VERSION ""

NS_ :

BS_:

BU_:

BO_ 2371550974 Chopper_Command: 8 Vector__XXX
 SG_ Faults_Clear : 2|2@1+ (1,0) [0|3] "" Vector__XXX
 SG_ Enable_Command : 0|2@1+ (1,0) [0|3] "" Vector__XXX

BO_ 2381595134 Chopper_State2: 8 Vector__XXX
 SG_ Chopper_Duty : 16|16@1+ (0.1,0) [0|100] "%" Vector__XXX
 SG_ Chopper_FSM_State : 0|16@1+ (1,0) [0|65535] "" Vector__XXX

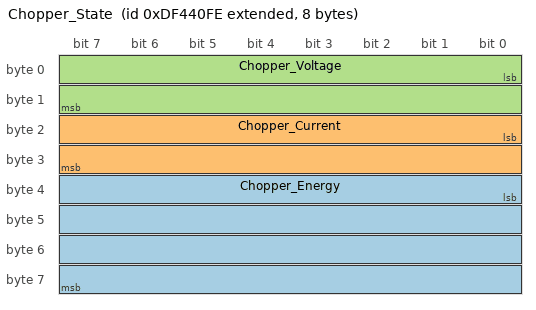
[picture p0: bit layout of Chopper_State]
BO_ 2381594878 Chopper_State: 8 Vector__XXX
 SG_ Chopper_Energy : 32|32@1+ (1,0) [0|4294967295] "J" Vector__XXX
 SG_ Chopper_Current : 16|16@1+ (0.1,0) [0|100] "Amps" Vector__XXX
 SG_ Chopper_Voltage : 0|16@1+ (0.1,0) [0|1000] "V" Vector__XXX

CM_ BO_ 2371550974 "Chopper command message";
CM_ SG_ 2371550974 Faults_Clear "Faults clear command";
CM_ SG_ 2371550974 Enable_Command "Turn on/off command";
CM_ BO_ 2381595134 "Second chopper state message";
CM_ SG_ 2381595134 Chopper_Duty "Current chopper's duty cycle";
CM_ SG_ 2381595134 Chopper_FSM_State "Current chopper's FSM state (0x0 - Initialization, 0x1 - Idle, 0x2 - Run, 0x8000 - Fault)";
CM_ BO_ 2381594878 "First chopper state message";
CM_ SG_ 2381594878 Chopper_Energy "Calculated energy dissipated on chopper resistor";
CM_ SG_ 2381594878 Chopper_Current "Calculated current through chopper resistor";
CM_ SG_ 2381594878 Chopper_Voltage "Calculated voltage on chopper resistor";
BA_DEF_ SG_  "SigType" ENUM  "Default","Range","RangeSigned","ASCII","Discrete","Control","ReferencePGN","DTC","StringDelimiter","StringLength","StringLengthControl","MessageCounter","MessageChecksum";
BA_DEF_ SG_  "GenSigEVName" STRING ;
BA_DEF_ SG_  "GenSigILSupport" ENUM  "No","Yes";
BA_DEF_ SG_  "GenSigSendType" ENUM  "Cyclic","OnWrite","OnWriteWithRepetition","OnChange","OnChangeWithRepetition","IfActive","IfActiveWithRepetition","NoSigSendType";
BA_DEF_ BO_  "GenMsgILSupport" ENUM  "No","Yes";
BA_DEF_ BU_  "NmStationAddress" INT 0 255;
BA_DEF_ BO_  "GenMsgSendType" ENUM  "cyclic","NotUsed","IfActive","NotUsed","NotUsed","NotUsed","NotUsed","NotUsed","noMsgSendType";
BA_DEF_ BO_  "GenMsgRequestable" INT 0 1;
BA_DEF_ BO_  "GenMsgCycleTime" INT 0 3600000;
BA_DEF_  "DBName" STRING ;
BA_DEF_  "BusType" STRING ;
BA_DEF_  "ProtocolType" STRING ;
BA_DEF_ BO_  "VFrameFormat" ENUM  "StandardCAN","ExtendedCAN","reserved","J1939PG";
BA_DEF_DEF_  "SigType" "Default";
BA_DEF_DEF_  "GenSigEVName" "Env@Nodename_@Signame";
BA_DEF_DEF_  "GenSigILSupport" "Yes";
BA_DEF_DEF_  "GenSigSendType" "NoSigSendType";
BA_DEF_DEF_  "GenMsgILSupport" "Yes";
BA_DEF_DEF_  "NmStationAddress" 254;
BA_DEF_DEF_  "GenMsgSendType" "noMsgSendType";
BA_DEF_DEF_  "GenMsgRequestable" 1;
BA_DEF_DEF_  "GenMsgCycleTime" 0;
BA_DEF_DEF_  "DBName" "";
BA_DEF_DEF_  "BusType" "CAN";
BA_DEF_DEF_  "ProtocolType" "J1939";
BA_DEF_DEF_  "VFrameFormat" "J1939PG";
BA_ "DBName" "Traction_Inverter_chopper";
BA_ "GenMsgCycleTime" BO_ 2371550974 100;
BA_ "GenMsgCycleTime" BO_ 2381595134 100;
BA_ "GenMsgCycleTime" BO_ 2381594878 100;
VAL_ 2371550974 Faults_Clear 3 "Clear Faults" 2 "TakeNoAction" 1 "TakeNoAction" 0 "TakeNoAction" ;
VAL_ 2371550974 Enable_Command 3 "Turn ON" 2 "Not Valid" 1 "Not Valid" 0 "Turn OFF" ;
